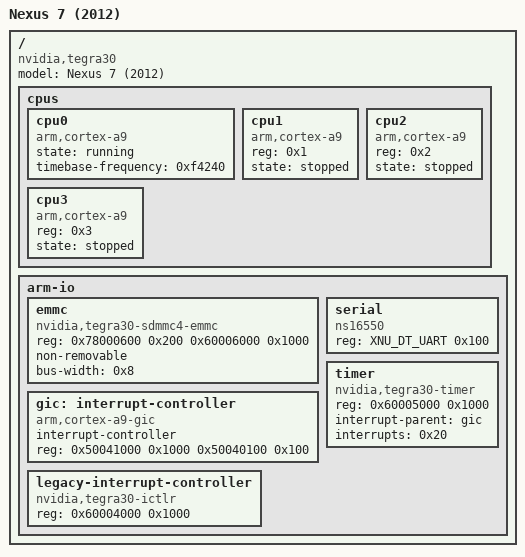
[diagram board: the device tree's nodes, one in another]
/* SPDX-License-Identifier: BSD-2-Clause */
/dts-v1/;
#ifndef XNU_DT_UART
#define XNU_DT_UART 0x70006000
#endif
#include "common.dtsi"

/ {
    model = "Nexus 7 (2012)";
    compatible = "nvidia,tegra30";
    cpus {
        cpu0 {
            compatible = "arm,cortex-a9";
            state = "running";
            timebase-frequency = <0xf4240>;
        };
        cpu1 {
            device_type = "cpu";
            compatible = "arm,cortex-a9";
            reg = <0x1>;
            state = "stopped";
        };
        cpu2 {
            device_type = "cpu";
            compatible = "arm,cortex-a9";
            reg = <0x2>;
            state = "stopped";
        };
        cpu3 {
            device_type = "cpu";
            compatible = "arm,cortex-a9";
            reg = <0x3>;
            state = "stopped";
        };
    };
    arm-io {
        emmc {
            compatible = "nvidia,tegra30-sdmmc4-emmc";
            reg = <0x78000600 0x200 0x60006000 0x1000>;
            non-removable;
            bus-width = <0x8>;
        };
        serial {
            device_type = "serial";
            compatible = "ns16550";
            reg = <XNU_DT_UART 0x100>;
        };
        timer {
            compatible = "nvidia,tegra30-timer";
            reg = <0x60005000 0x1000>;
            interrupt-parent = <&gic>;
            interrupts = <0x20>;
        };
        gic: interrupt-controller {
            compatible = "arm,cortex-a9-gic";
            /* Apple dtc generates AAPL,phandle for the label reference.
             * The platform uses one cell containing the absolute GIC ID. */
            interrupt-controller;
            #interrupt-cells = <0x1>;
            #address-cells = <0x0>;
            reg = <0x50041000 0x1000 0x50040100 0x100>;
        };
        legacy-interrupt-controller {
            compatible = "nvidia,tegra30-ictlr";
            reg = <0x60004000 0x1000>;
        };
    };
};
